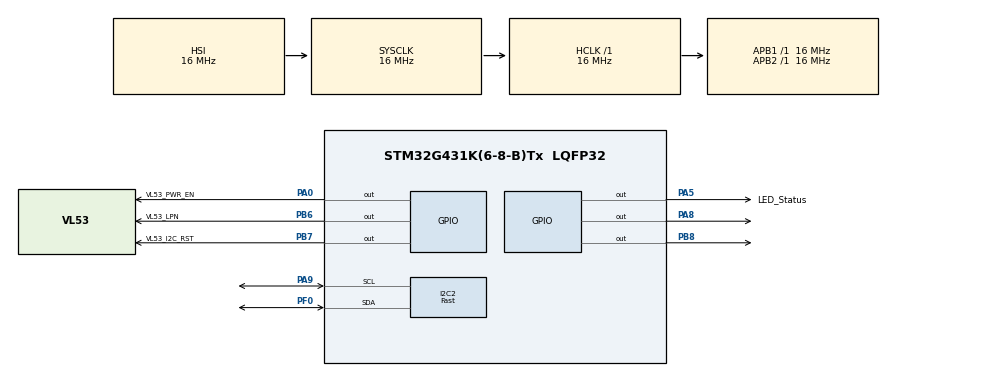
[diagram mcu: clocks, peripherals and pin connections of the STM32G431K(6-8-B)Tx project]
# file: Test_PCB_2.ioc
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I2C2.I2C_Speed_Mode=I2C_Fast
I2C2.Timing=0x00300617
Mcu.Family=STM32G4
Mcu.Name=STM32G431K(6-8-B)Tx
Mcu.Package=LQFP32
NVIC.PriorityGroup=NVIC_PRIORITYGROUP_4
PA0.GPIO_Label=VL53_PWR_EN
PA0.Signal=GPIO_Output
PA5.GPIO_Label=LED_Status
PA5.Signal=GPIO_Output
PA8.Signal=GPIO_Output
PA9.Mode=I2C
PA9.Signal=I2C2_SCL
PB6.GPIO_Label=VL53_LPN
PB6.Signal=GPIO_Output
PB7.GPIO_Label=VL53_I2C_RST
PB7.Signal=GPIO_Output
PB8-BOOT0.Signal=GPIO_Output
PF0-OSC_IN.Mode=I2C
PF0-OSC_IN.Signal=I2C2_SDA
ProjectManager.HeapSize=0x200
ProjectManager.StackSize=0x400
ProjectManager.TargetToolchain=STM32CubeIDE
RCC.AHBFreq_Value=16000000
RCC.APB1Freq_Value=16000000
RCC.APB1TimFreq_Value=16000000
RCC.APB2Freq_Value=16000000
RCC.APB2TimFreq_Value=16000000
RCC.CortexFreq_Value=16000000
RCC.EXTERNAL_CLOCK_VALUE=12288000
RCC.HCLKFreq_Value=16000000
RCC.HSE_VALUE=8000000
RCC.HSI48_VALUE=48000000
RCC.HSI_VALUE=16000000
RCC.LSE_VALUE=32768
RCC.SYSCLKFreq_VALUE=16000000
RCC.USBFreq_Value=64000000
RCC.VCOOutputFreq_Value=128000000
VP_SYS_VS_DBSignals.Mode=DisableDeadBatterySignals
board=custom

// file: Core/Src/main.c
/* USER CODE BEGIN Header */
/**
  ******************************************************************************
  * @file           : main.c
  * @brief          : Main program body
  ******************************************************************************
  * @attention
  *
  * Copyright (c) 2026 STMicroelectronics.
  * All rights reserved.
  *
  * This software is licensed under terms that can be found in the LICENSE file
  * in the root directory of this software component.
  * If no LICENSE file comes with this software, it is provided AS-IS.
  *
  ******************************************************************************
  */
/* USER CODE END Header */
#include "main.h"

I2C_HandleTypeDef hi2c2;

void SystemClock_Config(void);
static void MX_GPIO_Init(void);
static void MX_I2C2_Init(void);

int main(void)
{

  /* MCU Configuration--------------------------------------------------------*/

  /* Reset of all peripherals, Initializes the Flash interface and the Systick. */
  HAL_Init();

  /* Configure the system clock */
  SystemClock_Config();

  /* Initialize all configured peripherals */
  MX_GPIO_Init();
  MX_I2C2_Init();
  /* USER CODE BEGIN 2 */
  __HAL_RCC_GPIOA_CLK_ENABLE(); // Active l'horloge pour le Port A
  /* USER CODE END 2 */

  /* Infinite loop */
  while (1)
  {
	  /* Dans la boucle infinie du main.c */
	  while (1)
	  {
	      // Inverse l'état de la broche PA5 (Allume/Éteint)
	      HAL_GPIO_TogglePin(GPIOA, GPIO_PIN_5);

	      // Attend 500 millisecondes
	      HAL_Delay(500);
	  }
  }
}

void SystemClock_Config(void)
{
  RCC_OscInitTypeDef RCC_OscInitStruct = {0};
  RCC_ClkInitTypeDef RCC_ClkInitStruct = {0};

  /** Configure the main internal regulator output voltage
  */
  HAL_PWREx_ControlVoltageScaling(PWR_REGULATOR_VOLTAGE_SCALE1);

  /** Initializes the RCC Oscillators according to the specified parameters
  * in the RCC_OscInitTypeDef structure.
  */
  RCC_OscInitStruct.OscillatorType = RCC_OSCILLATORTYPE_HSI;
  RCC_OscInitStruct.HSIState = RCC_HSI_ON;
  RCC_OscInitStruct.HSICalibrationValue = RCC_HSICALIBRATION_DEFAULT;
  RCC_OscInitStruct.PLL.PLLState = RCC_PLL_NONE;
  if (HAL_RCC_OscConfig(&RCC_OscInitStruct) != HAL_OK)
  {
    Error_Handler();
  }

  /** Initializes the CPU, AHB and APB buses clocks
  */
  RCC_ClkInitStruct.ClockType = RCC_CLOCKTYPE_HCLK|RCC_CLOCKTYPE_SYSCLK
                              |RCC_CLOCKTYPE_PCLK1|RCC_CLOCKTYPE_PCLK2;
  RCC_ClkInitStruct.SYSCLKSource = RCC_SYSCLKSOURCE_HSI;
  RCC_ClkInitStruct.AHBCLKDivider = RCC_SYSCLK_DIV1;
  RCC_ClkInitStruct.APB1CLKDivider = RCC_HCLK_DIV1;
  RCC_ClkInitStruct.APB2CLKDivider = RCC_HCLK_DIV1;

  if (HAL_RCC_ClockConfig(&RCC_ClkInitStruct, FLASH_LATENCY_0) != HAL_OK)
  {
    Error_Handler();
  }
}

static void MX_I2C2_Init(void)
{

  hi2c2.Instance = I2C2;
  hi2c2.Init.Timing = 0x00300617;
  hi2c2.Init.OwnAddress1 = 0;
  hi2c2.Init.AddressingMode = I2C_ADDRESSINGMODE_7BIT;
  hi2c2.Init.DualAddressMode = I2C_DUALADDRESS_DISABLE;
  hi2c2.Init.OwnAddress2 = 0;
  hi2c2.Init.OwnAddress2Masks = I2C_OA2_NOMASK;
  hi2c2.Init.GeneralCallMode = I2C_GENERALCALL_DISABLE;
  hi2c2.Init.NoStretchMode = I2C_NOSTRETCH_DISABLE;
  if (HAL_I2C_Init(&hi2c2) != HAL_OK)
  {
    Error_Handler();
  }

  /** Configure Analogue filter
  */
  if (HAL_I2CEx_ConfigAnalogFilter(&hi2c2, I2C_ANALOGFILTER_ENABLE) != HAL_OK)
  {
    Error_Handler();
  }

  /** Configure Digital filter
  */
  if (HAL_I2CEx_ConfigDigitalFilter(&hi2c2, 0) != HAL_OK)
  {
    Error_Handler();
  }

}

static void MX_GPIO_Init(void)
{
  GPIO_InitTypeDef GPIO_InitStruct = {0};

  /* GPIO Ports Clock Enable */
  __HAL_RCC_GPIOF_CLK_ENABLE();
  __HAL_RCC_GPIOA_CLK_ENABLE();
  __HAL_RCC_GPIOB_CLK_ENABLE();

  /*Configure GPIO pin Output Level */
  HAL_GPIO_WritePin(GPIOA, VL53_PWR_EN_Pin|LED_Status_Pin|GPIO_PIN_8, GPIO_PIN_RESET);

  /*Configure GPIO pin Output Level */
  HAL_GPIO_WritePin(GPIOB, VL53_LPN_Pin|VL53_I2C_RST_Pin|GPIO_PIN_8, GPIO_PIN_RESET);

  /*Configure GPIO pins : VL53_PWR_EN_Pin LED_Status_Pin PA8 */
  GPIO_InitStruct.Pin = VL53_PWR_EN_Pin|LED_Status_Pin|GPIO_PIN_8;
  GPIO_InitStruct.Mode = GPIO_MODE_OUTPUT_PP;
  GPIO_InitStruct.Pull = GPIO_NOPULL;
  GPIO_InitStruct.Speed = GPIO_SPEED_FREQ_LOW;
  HAL_GPIO_Init(GPIOA, &GPIO_InitStruct);

  /*Configure GPIO pins : VL53_LPN_Pin VL53_I2C_RST_Pin PB8 */
  GPIO_InitStruct.Pin = VL53_LPN_Pin|VL53_I2C_RST_Pin|GPIO_PIN_8;
  GPIO_InitStruct.Mode = GPIO_MODE_OUTPUT_PP;
  GPIO_InitStruct.Pull = GPIO_NOPULL;
  GPIO_InitStruct.Speed = GPIO_SPEED_FREQ_LOW;
  HAL_GPIO_Init(GPIOB, &GPIO_InitStruct);

}

void Error_Handler(void)
{
  __disable_irq();
  while (1)
  {
  }
}
